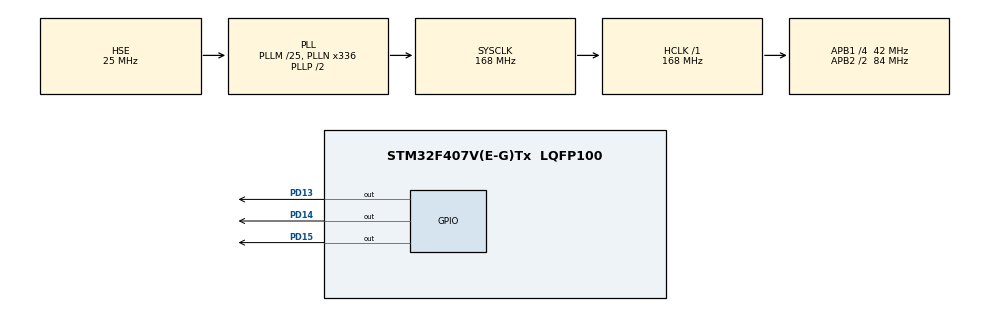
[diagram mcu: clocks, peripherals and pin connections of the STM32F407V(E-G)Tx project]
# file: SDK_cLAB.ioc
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Mcu.Family=STM32F4
RCC.PLLSourceVirtual=RCC_PLLSOURCE_HSE
PH0-OSC_IN.Signal=RCC_OSC_IN
RCC.CortexFreq_Value=168000000
PD15.GPIO_Speed=GPIO_SPEED_FREQ_HIGH
VP_IWDG_VS_IWDG.Mode=IWDG_Activate
RCC.APB1CLKDivider=RCC_HCLK_DIV4
RCC.SYSCLKSource=RCC_SYSCLKSOURCE_PLLCLK
ProjectManager.StackSize=0x400
PA13.Signal=SYS_JTMS-SWDIO
PD13.Signal=GPIO_Output
PD14.GPIO_Speed=GPIO_SPEED_FREQ_HIGH
ProjectManager.TargetToolchain=STM32CubeIDE
RCC.HCLKFreq_Value=168000000
RCC.APB2TimFreq_Value=168000000
RCC.LSE_VALUE=32768
RCC.AHBFreq_Value=168000000
PH0-OSC_IN.Mode=HSE-External-Oscillator
RCC.HSE_VALUE=25000000
PB3.Mode=JTAG_5_pins
board=custom
PD13.GPIO_Speed=GPIO_SPEED_FREQ_HIGH
RCC.VCOOutputFreq_Value=336000000
PA15.Mode=JTAG_5_pins
RCC.APB2Freq_Value=84000000
PB4.Mode=JTAG_5_pins
PA14.Mode=JTAG_5_pins
PH1-OSC_OUT.Signal=RCC_OSC_OUT
PA13.Mode=JTAG_5_pins
Mcu.Name=STM32F407V(E-G)Tx
PD14.Signal=GPIO_Output
PH1-OSC_OUT.Mode=HSE-External-Oscillator
RCC.48MHZClocksFreq_Value=84000000
PB3.Signal=SYS_JTDO-SWO
RCC.SYSCLKFreq_VALUE=168000000
Mcu.Package=LQFP100
PA14.Signal=SYS_JTCK-SWCLK
PA15.Signal=SYS_JTDI
ProjectManager.HeapSize=0x200
RCC.HSI_VALUE=16000000
NVIC.PriorityGroup=NVIC_PRIORITYGROUP_4
RCC.APB2CLKDivider=RCC_HCLK_DIV2
RCC.PLLM=25
RCC.PLLN=336
IWDG.Prescaler=IWDG_PRESCALER_64
RCC.APB1TimFreq_Value=84000000
RCC.APB1Freq_Value=42000000
PD15.Signal=GPIO_Output
PB4.Signal=SYS_JTRST

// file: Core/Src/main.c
/* USER CODE BEGIN Header */
/**
  ******************************************************************************
  * @file           : main.c
  * @brief          : Main program body
  ******************************************************************************
  * @attention
  *
  * <h2><center>&copy; Copyright (c) 2020 STMicroelectronics.
  * All rights reserved.</center></h2>
  *
  * This software component is licensed by ST under BSD 3-Clause license,
  * the "License"; You may not use this file except in compliance with the
  * License. You may obtain a copy of the License at:
  *                        opensource.org/licenses/BSD-3-Clause
  *
  ******************************************************************************
  */
#include "stdbool.h"
#include "stdio.h"
/* USER CODE END Header */
#include "main.h"
#include "iwdg.h"
#include "gpio.h"

/* USER CODE BEGIN Includes */
#include "trace.h"
/* USER CODE END Includes */

void SystemClock_Config(void);

/* USER CODE BEGIN 0 */
void Print_LED_State(int, bool);
/* USER CODE END 0 */

int main(void)
{

  /* MCU Configuration--------------------------------------------------------*/

  /* Reset of all peripherals, Initializes the Flash interface and the Systick. */
  HAL_Init();

  /* Configure the system clock */
  SystemClock_Config();

  /* Initialize all configured peripherals */
  MX_GPIO_Init();
  MX_IWDG_Init();
  /* USER CODE BEGIN 2 */

  /* Do not remove this code below */
  MX_TRACE_Init();
  SDK_TRACE_Start();
  /* Do not remove this code from above */

  /* Place your code from here */
  /* Example of using LED tracing */

  const int T1[] = { GPIO_PIN_3 };

  const int T2[] = { GPIO_PIN_3, GPIO_PIN_4 };
  const int T3[] = { GPIO_PIN_3, GPIO_PIN_4, GPIO_PIN_5 };
  const int T4[] = { GPIO_PIN_3, GPIO_PIN_4, GPIO_PIN_5, GPIO_PIN_6 };
  const int T5[] = { GPIO_PIN_3, GPIO_PIN_4, GPIO_PIN_5, GPIO_PIN_6, GPIO_PIN_8 };
  const int T6[] = { GPIO_PIN_3, GPIO_PIN_4, GPIO_PIN_5, GPIO_PIN_6, GPIO_PIN_8, GPIO_PIN_9 };
  const int T7[] = { GPIO_PIN_3, GPIO_PIN_4, GPIO_PIN_5, GPIO_PIN_6, GPIO_PIN_8, GPIO_PIN_9, GPIO_PIN_11 };
  const int T8[] = { GPIO_PIN_3, GPIO_PIN_4, GPIO_PIN_5, GPIO_PIN_6, GPIO_PIN_8, GPIO_PIN_9, GPIO_PIN_11, GPIO_PIN_12 };

  const int* transitions[] = { T1, T2, T3, T4, T5, T6, T7, T8 };
  const int led_events[] = { P0, P1, P2, P3, P4, P5, P6, P7 };

  for (int i = 0; i < 8; i++) {
	  for (int j = 0; j < i + 1; j++) {
		  HAL_GPIO_WritePin(GPIOD, transitions[i][j], GPIO_PIN_SET);
		  SDK_TRACE_Timestamp(led_events[j], 1);
	  }
	  Print_LED_State(i + 1, true);
	  HAL_Delay(100);
	  for (int j = 0; j < i + 1; j++) {
		  HAL_GPIO_WritePin(GPIOD, transitions[i][j], GPIO_PIN_RESET);
	  	  SDK_TRACE_Timestamp(led_events[j], 0);
	  }
	  Print_LED_State(i + 1, false);
  }

  for (int i = 6; i >= 0; i--) {
	  for (int j = 0; j < i + 1; j++) {
		  HAL_GPIO_WritePin(GPIOD, transitions[i][j], GPIO_PIN_SET);
		  SDK_TRACE_Timestamp(led_events[j], 1);
	  }
	  Print_LED_State(i + 1, true);
	  HAL_Delay(100);
	  for (int j = 0; j < i + 1; j++) {
	  	HAL_GPIO_WritePin(GPIOD, transitions[i][j], GPIO_PIN_RESET);
	  	SDK_TRACE_Timestamp(led_events[j], 0);
	  }
	  Print_LED_State(i + 1, false);
  }

  /* Place your code before here */
  /* Do not remove this code below */
  SDK_TRACE_Stop();
  /* Do not remove this code from above */

  /* USER CODE END 2 */

  /* Infinite loop */
  while (1)
  {

  }
}

void SystemClock_Config(void)
{
  RCC_OscInitTypeDef RCC_OscInitStruct = {0};
  RCC_ClkInitTypeDef RCC_ClkInitStruct = {0};

  /** Configure the main internal regulator output voltage
  */
  __HAL_RCC_PWR_CLK_ENABLE();
  __HAL_PWR_VOLTAGESCALING_CONFIG(PWR_REGULATOR_VOLTAGE_SCALE1);
  /** Initializes the RCC Oscillators according to the specified parameters
  * in the RCC_OscInitTypeDef structure.
  */
  RCC_OscInitStruct.OscillatorType = RCC_OSCILLATORTYPE_LSI|RCC_OSCILLATORTYPE_HSE;
  RCC_OscInitStruct.HSEState = RCC_HSE_ON;
  RCC_OscInitStruct.LSIState = RCC_LSI_ON;
  RCC_OscInitStruct.PLL.PLLState = RCC_PLL_ON;
  RCC_OscInitStruct.PLL.PLLSource = RCC_PLLSOURCE_HSE;
  RCC_OscInitStruct.PLL.PLLM = 25;
  RCC_OscInitStruct.PLL.PLLN = 336;
  RCC_OscInitStruct.PLL.PLLP = RCC_PLLP_DIV2;
  RCC_OscInitStruct.PLL.PLLQ = 4;
  if (HAL_RCC_OscConfig(&RCC_OscInitStruct) != HAL_OK)
  {
    Error_Handler();
  }
  /** Initializes the CPU, AHB and APB buses clocks
  */
  RCC_ClkInitStruct.ClockType = RCC_CLOCKTYPE_HCLK|RCC_CLOCKTYPE_SYSCLK
                              |RCC_CLOCKTYPE_PCLK1|RCC_CLOCKTYPE_PCLK2;
  RCC_ClkInitStruct.SYSCLKSource = RCC_SYSCLKSOURCE_PLLCLK;
  RCC_ClkInitStruct.AHBCLKDivider = RCC_SYSCLK_DIV1;
  RCC_ClkInitStruct.APB1CLKDivider = RCC_HCLK_DIV4;
  RCC_ClkInitStruct.APB2CLKDivider = RCC_HCLK_DIV2;

  if (HAL_RCC_ClockConfig(&RCC_ClkInitStruct, FLASH_LATENCY_5) != HAL_OK)
  {
    Error_Handler();
  }
}

/* USER CODE BEGIN 4 */
void Print_LED_State(int leds, bool is_set) {
	char str[200];
	sprintf(str, "LEDs %s:", is_set ? "on" : "off");
	for (int i = 0; i < leds; i++) {
		char led_string[15];
		sprintf(led_string, " LED%i", i + 1);
		strcat(str, led_string);
	}
	SDK_TRACE_Print(str);
}
/* USER CODE END 4 */

void Error_Handler(void)
{
}

/************************ (C) COPYRIGHT STMicroelectronics *****END OF FILE****/
